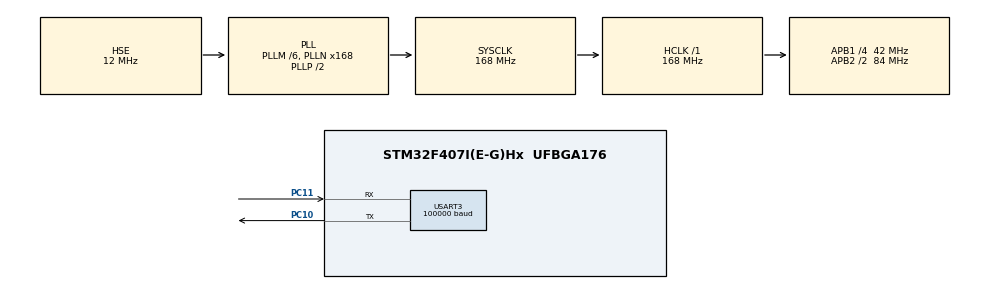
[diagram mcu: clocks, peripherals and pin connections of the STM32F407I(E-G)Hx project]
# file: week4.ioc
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Dma.Request0=USART3_RX
Dma.USART3_RX.0.Direction=DMA_PERIPH_TO_MEMORY
Dma.USART3_RX.0.FIFOMode=DMA_FIFOMODE_DISABLE
Dma.USART3_RX.0.Instance=DMA1_Stream1
Dma.USART3_RX.0.MemDataAlignment=DMA_MDATAALIGN_BYTE
Dma.USART3_RX.0.MemInc=DMA_MINC_ENABLE
Dma.USART3_RX.0.Mode=DMA_NORMAL
Dma.USART3_RX.0.PeriphDataAlignment=DMA_PDATAALIGN_BYTE
Dma.USART3_RX.0.PeriphInc=DMA_PINC_DISABLE
Dma.USART3_RX.0.Priority=DMA_PRIORITY_LOW
Mcu.Family=STM32F4
Mcu.Name=STM32F407I(E-G)Hx
Mcu.Package=UFBGA176
NVIC.DMA1_Stream1_IRQn=true\:0\:0\:false\:false\:true\:false\:true\:true
NVIC.PriorityGroup=NVIC_PRIORITYGROUP_4
NVIC.USART3_IRQn=true\:0\:0\:false\:false\:true\:true\:true\:true
PA13.Mode=Serial_Wire
PA13.Signal=SYS_JTMS-SWDIO
PA14.Mode=Serial_Wire
PA14.Signal=SYS_JTCK-SWCLK
PC10.Mode=Asynchronous
PC10.Signal=USART3_TX
PC11.Mode=Asynchronous
PC11.Signal=USART3_RX
PH0-OSC_IN.Mode=HSE-External-Oscillator
PH0-OSC_IN.Signal=RCC_OSC_IN
PH1-OSC_OUT.Mode=HSE-External-Oscillator
PH1-OSC_OUT.Signal=RCC_OSC_OUT
ProjectManager.HeapSize=0x200
ProjectManager.StackSize=0x400
ProjectManager.TargetToolchain=Makefile
RCC.48MHZClocksFreq_Value=84000000
RCC.AHBFreq_Value=168000000
RCC.APB1CLKDivider=RCC_HCLK_DIV4
RCC.APB1Freq_Value=42000000
RCC.APB1TimFreq_Value=84000000
RCC.APB2CLKDivider=RCC_HCLK_DIV2
RCC.APB2Freq_Value=84000000
RCC.APB2TimFreq_Value=168000000
RCC.CortexFreq_Value=168000000
RCC.HCLKFreq_Value=168000000
RCC.HSE_VALUE=12000000
RCC.HSI_VALUE=16000000
RCC.LSE_VALUE=32768
RCC.PLLM=6
RCC.PLLN=168
RCC.PLLSourceVirtual=RCC_PLLSOURCE_HSE
RCC.SYSCLKFreq_VALUE=168000000
RCC.SYSCLKSource=RCC_SYSCLKSOURCE_PLLCLK
RCC.VCOOutputFreq_Value=336000000
USART3.BaudRate=100000
USART3.Parity=PARITY_EVEN
USART3.StopBits=STOPBITS_2
USART3.VirtualMode=VM_ASYNC
USART3.WordLength=WORDLENGTH_9B
board=custom

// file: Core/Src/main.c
/* USER CODE BEGIN Header */
/**
  ******************************************************************************
  * @file           : main.c
  * @brief          : Main program body
  ******************************************************************************
  * @attention
  *
  * Copyright (c) 2026 STMicroelectronics.
  * All rights reserved.
  *
  * This software is licensed under terms that can be found in the LICENSE file
  * in the root directory of this software component.
  * If no LICENSE file comes with this software, it is provided AS-IS.
  *
  ******************************************************************************
  */
/* USER CODE END Header */
#include "main.h"
#include "dma.h"
#include "usart.h"
#include "gpio.h"

/* USER CODE BEGIN PD */
typedef struct
{
  int16_t rocker_l_;   // 左水平
  int16_t rocker_l1;   // 左竖直
  int16_t rocker_r_;   // 右水平
  int16_t rocker_r1;   // 右竖直

  int16_t SWA;         // 开关A
  int16_t SWB;         // 开关B
  int16_t SWC;         // 开关C
  int16_t SWD;         // 开关D

  int16_t VRA;         // 旋钮A
  int16_t VRB;         // 旋钮B

  uint8_t error_protect; // 故障保护激活位
  uint8_t byte_lose;     // 真丢失标志位
} RC_ctrl_t;

static RC_ctrl_t rc_data;       // 遥控器数据,初始化时返回

uint8_t buf[256];
int16_t CH[16];
uint8_t start_byte;
uint8_t flag_byte;
uint8_t stop_byte;

void HAL_UARTEx_RxEventCallback(UART_HandleTypeDef *huart, uint16_t Size)
{
  if(huart == &huart3)
  {
    start_byte = buf[0];

    CH[0]  = (((int16_t)buf[1]  >> 0 | ((int16_t)buf[2]  << 8))  & 0x07FF) - 1024;
    CH[1]  = (((int16_t)buf[2]  >> 3 | ((int16_t)buf[3]  << 5))  & 0x07FF) - 1024;
    CH[2]  = (((int16_t)buf[3]  >> 6 | ((int16_t)buf[4]  << 2) | ((int16_t)buf[5] << 10)) & 0x07FF) - 1024;
    CH[3]  = (((int16_t)buf[5]  >> 1 | ((int16_t)buf[6]  << 7))  & 0x07FF) - 1024;
    CH[4]  = (((int16_t)buf[6]  >> 4 | ((int16_t)buf[7]  << 4))  & 0x07FF) - 1024;
    CH[5]  = (((int16_t)buf[7]  >> 7 | ((int16_t)buf[8]  << 1) | ((int16_t)buf[9] << 9))  & 0x07FF) - 1024;
    CH[6]  = (((int16_t)buf[9]  >> 2 | ((int16_t)buf[10] << 6))  & 0x07FF) - 1024;
    CH[7]  = (((int16_t)buf[10] >> 5 | ((int16_t)buf[11] << 3))  & 0x07FF) - 1024;
    CH[8]  = (((int16_t)buf[12] >> 0 | ((int16_t)buf[13] << 8))  & 0x07FF) - 1024;
    CH[9]  = (((int16_t)buf[13] >> 3 | ((int16_t)buf[14] << 5))  & 0x07FF) - 1024;
    CH[10] = (((int16_t)buf[14] >> 6 | ((int16_t)buf[15] << 2) | ((int16_t)buf[16] << 10)) & 0x07FF) - 1024;
    CH[11] = (((int16_t)buf[16] >> 1 | ((int16_t)buf[17] << 7))  & 0x07FF) - 1024;
    CH[12] = (((int16_t)buf[17] >> 4 | ((int16_t)buf[18] << 4))  & 0x07FF) - 1024;
    CH[13] = (((int16_t)buf[18] >> 7 | ((int16_t)buf[19] << 1) | ((int16_t)buf[20] << 9))  & 0x07FF) - 1024;
    CH[14] = (((int16_t)buf[20] >> 2 | ((int16_t)buf[21] << 6))  & 0x07FF) - 1024;
    CH[15] = (((int16_t)buf[21] >> 5 | ((int16_t)buf[22] << 3))  & 0x07FF) - 1024;

  flag_byte = buf[23];  // 标志位

    flag_byte = buf[23];
    stop_byte = buf[24];

    rc_data.rocker_r_     = CH[0];                           // 右水平
    rc_data.rocker_r1     = CH[1];                           // 右竖直
    rc_data.rocker_l1     = CH[2];                           // 左竖直
    rc_data.rocker_l_     = CH[3];                           // 左水平
    rc_data.SWA           = CH[4];                           // 开关A
    rc_data.SWB           = CH[5];                           // 开关B
    rc_data.SWC           = CH[6];                           // 开关C
    rc_data.SWD           = CH[7];                           // 开关D
    rc_data.VRA           = CH[8];                           // 旋钮A
    rc_data.VRB           = CH[9];                           // 旋钮B
    rc_data.error_protect = (flag_byte >> 3) & 0x01;         // 故障保护激活位
    rc_data.byte_lose     = (flag_byte >> 2) & 0x01;         // 真丢失标志位

    HAL_UARTEx_ReceiveToIdle_DMA(&huart3, buf, 25);
    __HAL_DMA_DISABLE_IT(huart3.hdmarx, DMA_IT_HT);
  }
}

void HAL_UART_ErrorCallback(UART_HandleTypeDef *huart)
{
  if(huart == &huart3)
  {
    HAL_UARTEx_ReceiveToIdle_DMA(&huart3, buf, 25);
    __HAL_DMA_DISABLE_IT(huart3.hdmarx, DMA_IT_HT);
  }
}

/* USER CODE END PD */

void SystemClock_Config(void);

int main(void)
{

  /* MCU Configuration--------------------------------------------------------*/

  /* Reset of all peripherals, Initializes the Flash interface and the Systick. */
  HAL_Init();

  /* Configure the system clock */
  SystemClock_Config();

  /* Initialize all configured peripherals */
  MX_GPIO_Init();
  MX_DMA_Init();
  MX_USART3_UART_Init();
  /* USER CODE BEGIN 2 */
  HAL_UARTEx_ReceiveToIdle_DMA(&huart3, buf, 25); // Start UART reception in DMA mode with idle line detection
  __HAL_DMA_DISABLE_IT(huart3.hdmarx, DMA_IT_HT);  // Disable half-transfer interrupt
  /* USER CODE END 2 */

  /* Infinite loop */
  while (1)
  {

  }
}

void SystemClock_Config(void)
{
  RCC_OscInitTypeDef RCC_OscInitStruct = {0};
  RCC_ClkInitTypeDef RCC_ClkInitStruct = {0};

  /** Configure the main internal regulator output voltage
  */
  __HAL_RCC_PWR_CLK_ENABLE();
  __HAL_PWR_VOLTAGESCALING_CONFIG(PWR_REGULATOR_VOLTAGE_SCALE1);

  /** Initializes the RCC Oscillators according to the specified parameters
  * in the RCC_OscInitTypeDef structure.
  */
  RCC_OscInitStruct.OscillatorType = RCC_OSCILLATORTYPE_HSE;
  RCC_OscInitStruct.HSEState = RCC_HSE_ON;
  RCC_OscInitStruct.PLL.PLLState = RCC_PLL_ON;
  RCC_OscInitStruct.PLL.PLLSource = RCC_PLLSOURCE_HSE;
  RCC_OscInitStruct.PLL.PLLM = 6;
  RCC_OscInitStruct.PLL.PLLN = 168;
  RCC_OscInitStruct.PLL.PLLP = RCC_PLLP_DIV2;
  RCC_OscInitStruct.PLL.PLLQ = 4;
  if (HAL_RCC_OscConfig(&RCC_OscInitStruct) != HAL_OK)
  {
    Error_Handler();
  }

  /** Initializes the CPU, AHB and APB buses clocks
  */
  RCC_ClkInitStruct.ClockType = RCC_CLOCKTYPE_HCLK|RCC_CLOCKTYPE_SYSCLK
                              |RCC_CLOCKTYPE_PCLK1|RCC_CLOCKTYPE_PCLK2;
  RCC_ClkInitStruct.SYSCLKSource = RCC_SYSCLKSOURCE_PLLCLK;
  RCC_ClkInitStruct.AHBCLKDivider = RCC_SYSCLK_DIV1;
  RCC_ClkInitStruct.APB1CLKDivider = RCC_HCLK_DIV4;
  RCC_ClkInitStruct.APB2CLKDivider = RCC_HCLK_DIV2;

  if (HAL_RCC_ClockConfig(&RCC_ClkInitStruct, FLASH_LATENCY_5) != HAL_OK)
  {
    Error_Handler();
  }
}

void Error_Handler(void)
{
  __disable_irq();
  while (1)
  {
  }
}
